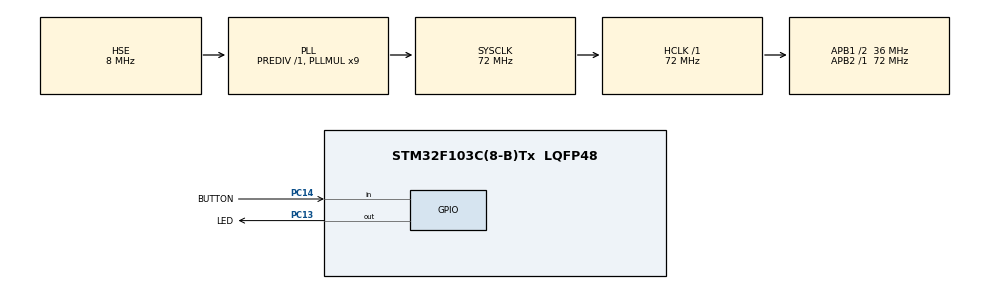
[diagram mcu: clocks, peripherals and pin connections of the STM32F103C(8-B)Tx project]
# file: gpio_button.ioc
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Mcu.Family=STM32F1
RCC.PLLSourceVirtual=RCC_PLLSOURCE_HSE
PD1-OSC_OUT.Mode=HSE-External-Oscillator
PC13-TAMPER-RTC.Signal=GPIO_Output
NVIC.TIM1_UP_IRQn=true\:0\:0\:false\:false\:true\:false\:true
PD0-OSC_IN.Signal=RCC_OSC_IN
RCC.APB1CLKDivider=RCC_HCLK_DIV2
PC14-OSC32_IN.Signal=GPIO_Input
RCC.SYSCLKSource=RCC_SYSCLKSOURCE_PLLCLK
ProjectManager.StackSize=0x400
PD1-OSC_OUT.Signal=RCC_OSC_OUT
PA13.Signal=SYS_JTMS-SWDIO
ProjectManager.TargetToolchain=STM32CubeIDE
RCC.HCLKFreq_Value=72000000
RCC.APB2TimFreq_Value=72000000
RCC.USBFreq_Value=72000000
RCC.AHBFreq_Value=72000000
PD0-OSC_IN.Mode=HSE-External-Oscillator
board=custom
RCC.PLLMUL=RCC_PLL_MUL9
PC13-TAMPER-RTC.GPIO_Label=LED
RCC.APB2Freq_Value=72000000
PA14.Mode=Serial_Wire
VP_SYS_VS_tim1.Mode=TIM1
PA13.Mode=Serial_Wire
Mcu.Name=STM32F103C(8-B)Tx
RCC.SYSCLKFreq_VALUE=72000000
Mcu.Package=LQFP48
NVIC.TimeBase=TIM1_UP_IRQn
NVIC.TimeBaseIP=TIM1
PA14.Signal=SYS_JTCK-SWCLK
ProjectManager.HeapSize=0x200
NVIC.PriorityGroup=NVIC_PRIORITYGROUP_4
RCC.APB1TimFreq_Value=72000000
PC14-OSC32_IN.GPIO_PuPd=GPIO_PULLDOWN
PC14-OSC32_IN.GPIO_Label=BUTTON
RCC.APB1Freq_Value=36000000

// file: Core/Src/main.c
/* USER CODE BEGIN Header */
/**

  The following program turns on a led when you push a button, otherwise the led is off.

  */
/* USER CODE END Header */
#include "main.h"

/* USER CODE BEGIN Includes */
#include "FreeRTOS.h"
#include "task.h"
/* USER CODE END Includes */

void SystemClock_Config(void);
static void MX_GPIO_Init(void);

/* USER CODE BEGIN 0 */

static void Button(void *pvParameters){

	while (1){

		if (HAL_GPIO_ReadPin(BUTTON_GPIO_Port, BUTTON_Pin)){

			// Debounce delay
			vTaskDelay(150/portTICK_PERIOD_MS);

			if (HAL_GPIO_ReadPin(BUTTON_GPIO_Port, BUTTON_Pin)){
				// Turn on the led
				HAL_GPIO_WritePin(LED_GPIO_Port, LED_Pin, 0);
			}

		}

		else {
			// Turn off the led
			HAL_GPIO_WritePin(LED_GPIO_Port, LED_Pin, 1);
		}
	}
}

/* USER CODE END 0 */

int main(void)
{

  /* MCU Configuration--------------------------------------------------------*/

  /* Reset of all peripherals, Initializes the Flash interface and the Systick. */
  HAL_Init();

  /* Configure the system clock */
  SystemClock_Config();

  /* Initialize all configured peripherals */
  MX_GPIO_Init();
  /* USER CODE BEGIN 2 */

  xTaskCreate(Button, "",
    		  configMINIMAL_STACK_SIZE,
    		  NULL,
    		  1,
    		  NULL);

  vTaskStartScheduler();

  /* USER CODE END 2 */

  /* Infinite loop */
  while (1)
  {

  }
}

void SystemClock_Config(void)
{
  RCC_OscInitTypeDef RCC_OscInitStruct = {0};
  RCC_ClkInitTypeDef RCC_ClkInitStruct = {0};

  /** Initializes the RCC Oscillators according to the specified parameters
  * in the RCC_OscInitTypeDef structure.
  */
  RCC_OscInitStruct.OscillatorType = RCC_OSCILLATORTYPE_HSE;
  RCC_OscInitStruct.HSEState = RCC_HSE_ON;
  RCC_OscInitStruct.HSEPredivValue = RCC_HSE_PREDIV_DIV1;
  RCC_OscInitStruct.HSIState = RCC_HSI_ON;
  RCC_OscInitStruct.PLL.PLLState = RCC_PLL_ON;
  RCC_OscInitStruct.PLL.PLLSource = RCC_PLLSOURCE_HSE;
  RCC_OscInitStruct.PLL.PLLMUL = RCC_PLL_MUL9;
  if (HAL_RCC_OscConfig(&RCC_OscInitStruct) != HAL_OK)
  {
    Error_Handler();
  }
  /** Initializes the CPU, AHB and APB buses clocks
  */
  RCC_ClkInitStruct.ClockType = RCC_CLOCKTYPE_HCLK|RCC_CLOCKTYPE_SYSCLK
                              |RCC_CLOCKTYPE_PCLK1|RCC_CLOCKTYPE_PCLK2;
  RCC_ClkInitStruct.SYSCLKSource = RCC_SYSCLKSOURCE_PLLCLK;
  RCC_ClkInitStruct.AHBCLKDivider = RCC_SYSCLK_DIV1;
  RCC_ClkInitStruct.APB1CLKDivider = RCC_HCLK_DIV2;
  RCC_ClkInitStruct.APB2CLKDivider = RCC_HCLK_DIV1;

  if (HAL_RCC_ClockConfig(&RCC_ClkInitStruct, FLASH_LATENCY_2) != HAL_OK)
  {
    Error_Handler();
  }
}

static void MX_GPIO_Init(void)
{
  GPIO_InitTypeDef GPIO_InitStruct = {0};

  /* GPIO Ports Clock Enable */
  __HAL_RCC_GPIOC_CLK_ENABLE();
  __HAL_RCC_GPIOD_CLK_ENABLE();
  __HAL_RCC_GPIOA_CLK_ENABLE();

  /*Configure GPIO pin Output Level */
  HAL_GPIO_WritePin(LED_GPIO_Port, LED_Pin, GPIO_PIN_RESET);

  /*Configure GPIO pin : LED_Pin */
  GPIO_InitStruct.Pin = LED_Pin;
  GPIO_InitStruct.Mode = GPIO_MODE_OUTPUT_PP;
  GPIO_InitStruct.Pull = GPIO_NOPULL;
  GPIO_InitStruct.Speed = GPIO_SPEED_FREQ_LOW;
  HAL_GPIO_Init(LED_GPIO_Port, &GPIO_InitStruct);

  /*Configure GPIO pin : BUTTON_Pin */
  GPIO_InitStruct.Pin = BUTTON_Pin;
  GPIO_InitStruct.Mode = GPIO_MODE_INPUT;
  GPIO_InitStruct.Pull = GPIO_PULLDOWN;
  HAL_GPIO_Init(BUTTON_GPIO_Port, &GPIO_InitStruct);

}

 /**
  * @brief  Period elapsed callback in non blocking mode
  * @note   This function is called  when TIM1 interrupt took place, inside
  * HAL_TIM_IRQHandler(). It makes a direct call to HAL_IncTick() to increment
  * a global variable "uwTick" used as application time base.
  * @param  htim : TIM handle
  * @retval None
  */
void HAL_TIM_PeriodElapsedCallback(TIM_HandleTypeDef *htim)
{
  if (htim->Instance == TIM1) {
    HAL_IncTick();
  }
}

void Error_Handler(void)
{
  __disable_irq();
  while (1)
  {
  }
}

/************************ (C) COPYRIGHT STMicroelectronics *****END OF FILE****/
